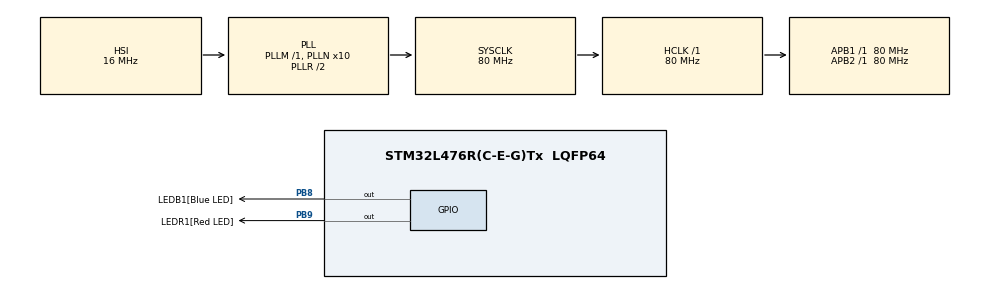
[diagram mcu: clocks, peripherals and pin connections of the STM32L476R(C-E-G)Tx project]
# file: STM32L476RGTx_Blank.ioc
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Mcu.Family=STM32L4
RCC.MSI_VALUE=4000000
RCC.PLLSourceVirtual=RCC_PLLSOURCE_HSI
PA14\ (JTCK-SWCLK).Mode=Trace_Asynchronous_SW
VP_SYS_VS_tim6.Mode=TIM6
RCC.CortexFreq_Value=80000000
FREERTOS.Tasks01=defaultTask,24,128,StartDefaultTask,Default,NULL,Dynamic,NULL,NULL;BlinkRed,24,128,StartBlinkRed,Default,NULL,Dynamic,NULL,NULL;BlinkBlue,16,128,StartBlinkBlue,Default,NULL,Dynamic,NULL,NULL
FREERTOS.BinarySemaphores01=BlinkSemaphore,Dynamic,NULL
PB9.GPIO_Label=LEDR1[Red LED]
NVIC.TIM6_DAC_IRQn=true\:0\:0\:false\:false\:true\:false\:false\:true
RCC.SYSCLKSource=RCC_SYSCLKSOURCE_PLLCLK
ProjectManager.StackSize=0x400
PB3\ (JTDO-TRACESWO).Signal=SYS_JTDO-SWO
VP_FREERTOS_VS_CMSIS_V2.Mode=CMSIS_V2
PA14\ (JTCK-SWCLK).Signal=SYS_JTCK-SWCLK
PB8.GPIO_Label=LEDB1[Blue LED]
ProjectManager.TargetToolchain=STM32CubeIDE
RCC.HCLKFreq_Value=80000000
RCC.APB2TimFreq_Value=80000000
RCC.USBFreq_Value=64000000
RCC.LSE_VALUE=32768
RCC.AHBFreq_Value=80000000
RCC.HSE_VALUE=8000000
board=custom
RCC.VCOOutputFreq_Value=160000000
RCC.APB2Freq_Value=80000000
PB3\ (JTDO-TRACESWO).Mode=Trace_Asynchronous_SW
RCC.ADCFreq_Value=64000000
Mcu.Name=STM32L476R(C-E-G)Tx
PA13\ (JTMS-SWDIO).Mode=Trace_Asynchronous_SW
RCC.SYSCLKFreq_VALUE=80000000
Mcu.Package=LQFP64
PB9.Signal=GPIO_Output
NVIC.TimeBase=TIM6_DAC_IRQn
NVIC.TimeBaseIP=TIM6
ProjectManager.HeapSize=0x200
RCC.HSI_VALUE=16000000
NVIC.PriorityGroup=NVIC_PRIORITYGROUP_4
RCC.PLLN=10
RCC.APB1TimFreq_Value=80000000
PB8.Signal=GPIO_Output
PA13\ (JTMS-SWDIO).Signal=SYS_JTMS-SWDIO
RCC.APB1Freq_Value=80000000

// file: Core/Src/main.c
/* USER CODE BEGIN Header */
/**
  ******************************************************************************
  * @file           : main.c
  * @brief          : Main program body
  ******************************************************************************
  * @attention
  *
  * <h2><center>&copy; Copyright (c) 2022 STMicroelectronics.
  * All rights reserved.</center></h2>
  *
  * This software component is licensed by ST under BSD 3-Clause license,
  * the "License"; You may not use this file except in compliance with the
  * License. You may obtain a copy of the License at:
  *                        opensource.org/licenses/BSD-3-Clause
  *
  ******************************************************************************
  */
/* USER CODE END Header */
#include "main.h"
#include "cmsis_os.h"

/* USER CODE BEGIN Includes */

#include "stdio.h"

/* USER CODE END Includes */

/* Definitions for defaultTask */
osThreadId_t defaultTaskHandle;
const osThreadAttr_t defaultTask_attributes = {
  .name = "defaultTask",
  .priority = (osPriority_t) osPriorityNormal,
  .stack_size = 128 * 4
};
/* Definitions for BlinkRed */
osThreadId_t BlinkRedHandle;
const osThreadAttr_t BlinkRed_attributes = {
  .name = "BlinkRed",
  .priority = (osPriority_t) osPriorityNormal,
  .stack_size = 128 * 4
};
/* Definitions for BlinkBlue */
osThreadId_t BlinkBlueHandle;
const osThreadAttr_t BlinkBlue_attributes = {
  .name = "BlinkBlue",
  .priority = (osPriority_t) osPriorityBelowNormal,
  .stack_size = 128 * 4
};
/* Definitions for BlinkSemaphore */
osSemaphoreId_t BlinkSemaphoreHandle;
const osSemaphoreAttr_t BlinkSemaphore_attributes = {
  .name = "BlinkSemaphore"
};

void SystemClock_Config(void);
static void MX_GPIO_Init(void);
void StartDefaultTask(void *argument);
void StartBlinkRed(void *argument);
void StartBlinkBlue(void *argument);

/* USER CODE BEGIN 0 */

int __io_putchar(int ch)
{
	ITM_SendChar(ch);
	return(ch);
}

uint8_t i=0;

/* USER CODE END 0 */

int main(void)
{
  /* USER CODE BEGIN 1 */
	printf("Starting scheduler\n");
  /* USER CODE END 1 */

  /* MCU Configuration--------------------------------------------------------*/

  /* Reset of all peripherals, Initializes the Flash interface and the Systick. */
  HAL_Init();

  /* Configure the system clock */
  SystemClock_Config();

  /* Initialize all configured peripherals */
  MX_GPIO_Init();

  /* Init scheduler */
  osKernelInitialize();

  /* Create the semaphores(s) */
  /* creation of BlinkSemaphore */
  BlinkSemaphoreHandle = osSemaphoreNew(1, 1, &BlinkSemaphore_attributes);

  /* Create the thread(s) */
  /* creation of defaultTask */
  defaultTaskHandle = osThreadNew(StartDefaultTask, NULL, &defaultTask_attributes);

  /* creation of BlinkRed */
  BlinkRedHandle = osThreadNew(StartBlinkRed, NULL, &BlinkRed_attributes);

  /* creation of BlinkBlue */
  BlinkBlueHandle = osThreadNew(StartBlinkBlue, NULL, &BlinkBlue_attributes);

  /* Start scheduler */
  osKernelStart();

  /* We should never get here as control is now taken by the scheduler */
  /* Infinite loop */
  while (1)
  {

  }
}

void SystemClock_Config(void)
{
  RCC_OscInitTypeDef RCC_OscInitStruct = {0};
  RCC_ClkInitTypeDef RCC_ClkInitStruct = {0};

  /** Initializes the RCC Oscillators according to the specified parameters
  * in the RCC_OscInitTypeDef structure.
  */
  RCC_OscInitStruct.OscillatorType = RCC_OSCILLATORTYPE_HSI;
  RCC_OscInitStruct.HSIState = RCC_HSI_ON;
  RCC_OscInitStruct.HSICalibrationValue = RCC_HSICALIBRATION_DEFAULT;
  RCC_OscInitStruct.PLL.PLLState = RCC_PLL_ON;
  RCC_OscInitStruct.PLL.PLLSource = RCC_PLLSOURCE_HSI;
  RCC_OscInitStruct.PLL.PLLM = 1;
  RCC_OscInitStruct.PLL.PLLN = 10;
  RCC_OscInitStruct.PLL.PLLP = RCC_PLLP_DIV7;
  RCC_OscInitStruct.PLL.PLLQ = RCC_PLLQ_DIV2;
  RCC_OscInitStruct.PLL.PLLR = RCC_PLLR_DIV2;
  if (HAL_RCC_OscConfig(&RCC_OscInitStruct) != HAL_OK)
  {
    Error_Handler();
  }
  /** Initializes the CPU, AHB and APB buses clocks
  */
  RCC_ClkInitStruct.ClockType = RCC_CLOCKTYPE_HCLK|RCC_CLOCKTYPE_SYSCLK
                              |RCC_CLOCKTYPE_PCLK1|RCC_CLOCKTYPE_PCLK2;
  RCC_ClkInitStruct.SYSCLKSource = RCC_SYSCLKSOURCE_PLLCLK;
  RCC_ClkInitStruct.AHBCLKDivider = RCC_SYSCLK_DIV1;
  RCC_ClkInitStruct.APB1CLKDivider = RCC_HCLK_DIV1;
  RCC_ClkInitStruct.APB2CLKDivider = RCC_HCLK_DIV1;

  if (HAL_RCC_ClockConfig(&RCC_ClkInitStruct, FLASH_LATENCY_4) != HAL_OK)
  {
    Error_Handler();
  }
  /** Configure the main internal regulator output voltage
  */
  if (HAL_PWREx_ControlVoltageScaling(PWR_REGULATOR_VOLTAGE_SCALE1) != HAL_OK)
  {
    Error_Handler();
  }
}

static void MX_GPIO_Init(void)
{
  GPIO_InitTypeDef GPIO_InitStruct = {0};

  /* GPIO Ports Clock Enable */
  __HAL_RCC_GPIOA_CLK_ENABLE();
  __HAL_RCC_GPIOB_CLK_ENABLE();

  /*Configure GPIO pin Output Level */
  HAL_GPIO_WritePin(GPIOB, LEDB1_Pin|LEDR1_Pin, GPIO_PIN_RESET);

  /*Configure GPIO pins : LEDB1_Pin LEDR1_Pin */
  GPIO_InitStruct.Pin = LEDB1_Pin|LEDR1_Pin;
  GPIO_InitStruct.Mode = GPIO_MODE_OUTPUT_PP;
  GPIO_InitStruct.Pull = GPIO_NOPULL;
  GPIO_InitStruct.Speed = GPIO_SPEED_FREQ_LOW;
  HAL_GPIO_Init(GPIOB, &GPIO_InitStruct);

}

void StartDefaultTask(void *argument)
{
  for(;;)
  {
    osDelay(1);
  }
}

void StartBlinkRed(void *argument)
{
  /* USER CODE BEGIN StartBlinkRed */
  /* Infinite loop */
  for(;;)
  {
	  printf("/*----------------------*/\n");
	  printf("Entering BlinkRed task\n");
	  printf("Waiting for semaphore\n");

	  osSemaphoreAcquire(BlinkSemaphoreHandle, osWaitForever);

	  printf("Semaphore acquired\n");

	  HAL_GPIO_TogglePin(LEDR1_GPIO_Port, LEDR1_Pin);

	  printf("LEDR1_Pin toggled\n");
	  printf("Initiating 1s OS delay\n");

	  osDelay(1000);

	  printf("OS delay of 1s passed, continuing with BlinkRed task\n");

	  HAL_GPIO_TogglePin(LEDR1_GPIO_Port, LEDR1_Pin);

	  printf("LEDR1_Pin toggled\n");

	  osSemaphoreRelease(BlinkSemaphoreHandle);

	  printf("Semaphore released(BlinkRed task)\n");

	  printf("Initiating 1s OS delay\n");

	  osDelay(1000);

	  printf("OS delay of 1s passed, continuing with BlinkRed task\n");
	  printf("Leaving BlinkRed task\n");
  }
  /* USER CODE END StartBlinkRed */
}

void StartBlinkBlue(void *argument)
{
  /* USER CODE BEGIN StartBlinkBlue */
  /* Infinite loop */
  for(;;)
  {
	  printf("/*----------------------*/\n");
	  printf("Entering BlinkBlue task\n");
	  printf("Waiting for semaphore\n");

	  osSemaphoreAcquire(BlinkSemaphoreHandle, osWaitForever);

	  printf("Semaphore acquired\n");

	  HAL_GPIO_TogglePin(LEDB1_GPIO_Port, LEDB1_Pin);

	  printf("LEDB1_Pin toggled\n");
	  printf("Initiating 1s OS delay\n");

	  osDelay(1000);

	  printf("OS delay of 1s passed, continuing with BlinkBlue task\n");

	  HAL_GPIO_TogglePin(LEDB1_GPIO_Port, LEDB1_Pin);

	  printf("LEDB1_Pin toggled\n");

	  osSemaphoreRelease(BlinkSemaphoreHandle);

	  printf("Semaphore released(BlinkBlue task)\n");
	  printf("Initiating 1s OS delay\n");

	  osDelay(1000);

	  printf("OS delay of 1s passed, continuing with BlinkBlue task\n");
	  printf("Leaving BlinkBlue task\n");
  }
  /* USER CODE END StartBlinkBlue */
}

 /**
  * @brief  Period elapsed callback in non blocking mode
  * @note   This function is called  when TIM6 interrupt took place, inside
  * HAL_TIM_IRQHandler(). It makes a direct call to HAL_IncTick() to increment
  * a global variable "uwTick" used as application time base.
  * @param  htim : TIM handle
  * @retval None
  */
void HAL_TIM_PeriodElapsedCallback(TIM_HandleTypeDef *htim)
{
  if (htim->Instance == TIM6) {
    HAL_IncTick();
  }
}

void Error_Handler(void)
{
  __disable_irq();
  while (1)
  {
  }
}

/************************ (C) COPYRIGHT STMicroelectronics *****END OF FILE****/
